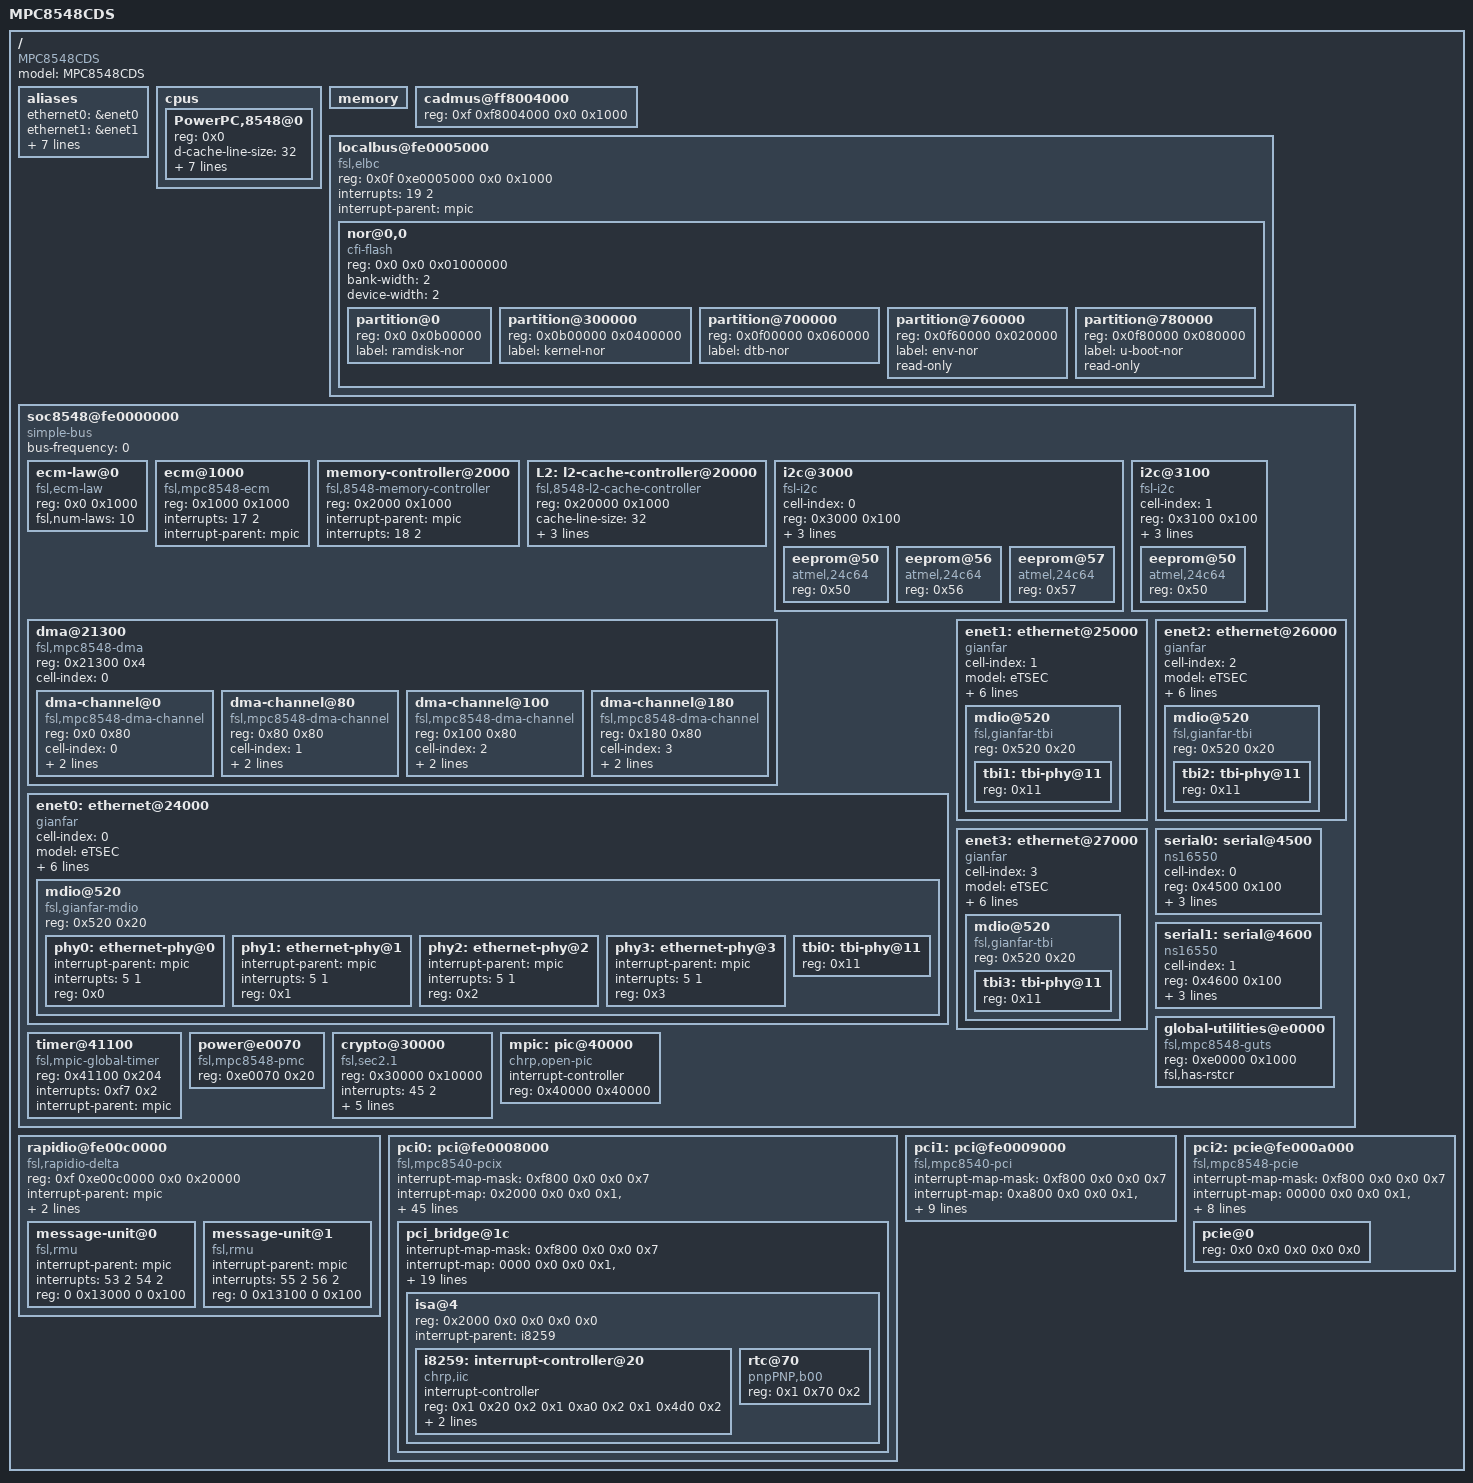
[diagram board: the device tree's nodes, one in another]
/*
 * MPC8548 CDS Device Tree Source
 *
 * Copyright 2011 Freescale Semiconductor Inc.
 *
 * This program is free software; you can redistribute  it and/or modify it
 * under  the terms of  the GNU General  Public License as published by the
 * Free Software Foundation;  either version 2 of the  License, or (at your
 * option) any later version.
 */

/dts-v1/;

/ {
	model = "MPC8548CDS";
	compatible = "MPC8548CDS", "MPC85xxCDS";
	#address-cells = <2>;
	#size-cells = <2>;

	aliases {
		ethernet0 = &enet0;
		ethernet1 = &enet1;
		ethernet2 = &enet2;
		ethernet3 = &enet3;
		serial0 = &serial0;
		serial1 = &serial1;
		pci0 = &pci0;
		pci1 = &pci1;
		pci2 = &pci2;
	};

	cpus {
		#address-cells = <1>;
		#size-cells = <0>;

		PowerPC,8548@0 {
			device_type = "cpu";
			reg = <0x0>;
			d-cache-line-size = <32>;	// 32 bytes
			i-cache-line-size = <32>;	// 32 bytes
			d-cache-size = <0x8000>;		// L1, 32K
			i-cache-size = <0x8000>;		// L1, 32K
			timebase-frequency = <0>;	//  33 MHz, from uboot
			bus-frequency = <0>;	// 166 MHz
			clock-frequency = <0>;	// 825 MHz, from uboot
			next-level-cache = <&L2>;
		};
	};

	memory {
		device_type = "memory";
	};

	cadmus@ff8004000 {
		device_type = "cadmus";
		reg = <0xf 0xf8004000 0x0 0x1000>;
	};

	localbus@fe0005000 {
		#address-cells = <2>;
		#size-cells = <1>;
		compatible = "fsl,elbc", "simple-bus";
		reg = <0x0f 0xe0005000 0x0 0x1000>;
		interrupts = <19 2>;
		interrupt-parent = <&mpic>;

		ranges = <0x0 0x0 0x0f 0xff000000 0x01000000>;

		nor@0,0 {
			#address-cells = <1>;
			#size-cells = <1>;
			compatible = "cfi-flash";
			reg = <0x0 0x0 0x01000000>;
			bank-width = <2>;
			device-width = <2>;

			partition@0 {
				reg = <0x0 0x0b00000>;
				label = "ramdisk-nor";
			};

			partition@300000 {
				reg = <0x0b00000 0x0400000>;
				label = "kernel-nor";
			};

			partition@700000 {
				reg = <0x0f00000 0x060000>;
				label = "dtb-nor";
			};

			partition@760000 {
				reg = <0x0f60000 0x020000>;
				label = "env-nor";
				read-only;
			};

			partition@780000 {
				reg = <0x0f80000 0x080000>;
				label = "u-boot-nor";
				read-only;
			};
		};
	};

	soc8548@fe0000000 {
		#address-cells = <1>;
		#size-cells = <1>;
		device_type = "soc";
		compatible = "simple-bus";
		ranges = <0x0 0xf 0xe0000000 0x100000>;
		bus-frequency = <0>;

		ecm-law@0 {
			compatible = "fsl,ecm-law";
			reg = <0x0 0x1000>;
			fsl,num-laws = <10>;
		};

		ecm@1000 {
			compatible = "fsl,mpc8548-ecm", "fsl,ecm";
			reg = <0x1000 0x1000>;
			interrupts = <17 2>;
			interrupt-parent = <&mpic>;
		};

		memory-controller@2000 {
			compatible = "fsl,8548-memory-controller";
			reg = <0x2000 0x1000>;
			interrupt-parent = <&mpic>;
			interrupts = <18 2>;
		};

		L2: l2-cache-controller@20000 {
			compatible = "fsl,8548-l2-cache-controller";
			reg = <0x20000 0x1000>;
			cache-line-size = <32>;	// 32 bytes
			cache-size = <0x80000>;	// L2, 512K
			interrupt-parent = <&mpic>;
			interrupts = <16 2>;
		};

		i2c@3000 {
			#address-cells = <1>;
			#size-cells = <0>;
			cell-index = <0>;
			compatible = "fsl-i2c";
			reg = <0x3000 0x100>;
			interrupts = <43 2>;
			interrupt-parent = <&mpic>;
			dfsrr;

			eeprom@50 {
				compatible = "atmel,24c64";
				reg = <0x50>;
			};

			eeprom@56 {
				compatible = "atmel,24c64";
				reg = <0x56>;
			};

			eeprom@57 {
				compatible = "atmel,24c64";
				reg = <0x57>;
			};
		};

		i2c@3100 {
			#address-cells = <1>;
			#size-cells = <0>;
			cell-index = <1>;
			compatible = "fsl-i2c";
			reg = <0x3100 0x100>;
			interrupts = <43 2>;
			interrupt-parent = <&mpic>;
			dfsrr;

			eeprom@50 {
				compatible = "atmel,24c64";
				reg = <0x50>;
			};
		};

		dma@21300 {
			#address-cells = <1>;
			#size-cells = <1>;
			compatible = "fsl,mpc8548-dma", "fsl,eloplus-dma";
			reg = <0x21300 0x4>;
			ranges = <0x0 0x21100 0x200>;
			cell-index = <0>;
			dma-channel@0 {
				compatible = "fsl,mpc8548-dma-channel",
						"fsl,eloplus-dma-channel";
				reg = <0x0 0x80>;
				cell-index = <0>;
				interrupt-parent = <&mpic>;
				interrupts = <20 2>;
			};
			dma-channel@80 {
				compatible = "fsl,mpc8548-dma-channel",
						"fsl,eloplus-dma-channel";
				reg = <0x80 0x80>;
				cell-index = <1>;
				interrupt-parent = <&mpic>;
				interrupts = <21 2>;
			};
			dma-channel@100 {
				compatible = "fsl,mpc8548-dma-channel",
						"fsl,eloplus-dma-channel";
				reg = <0x100 0x80>;
				cell-index = <2>;
				interrupt-parent = <&mpic>;
				interrupts = <22 2>;
			};
			dma-channel@180 {
				compatible = "fsl,mpc8548-dma-channel",
						"fsl,eloplus-dma-channel";
				reg = <0x180 0x80>;
				cell-index = <3>;
				interrupt-parent = <&mpic>;
				interrupts = <23 2>;
			};
		};

		enet0: ethernet@24000 {
			#address-cells = <1>;
			#size-cells = <1>;
			cell-index = <0>;
			device_type = "network";
			model = "eTSEC";
			compatible = "gianfar";
			reg = <0x24000 0x1000>;
			ranges = <0x0 0x24000 0x1000>;
			local-mac-address = [ 00 00 00 00 00 00 ];
			interrupts = <29 2 30 2 34 2>;
			interrupt-parent = <&mpic>;
			tbi-handle = <&tbi0>;
			phy-handle = <&phy0>;

			mdio@520 {
				#address-cells = <1>;
				#size-cells = <0>;
				compatible = "fsl,gianfar-mdio";
				reg = <0x520 0x20>;

				phy0: ethernet-phy@0 {
					interrupt-parent = <&mpic>;
					interrupts = <5 1>;
					reg = <0x0>;
					device_type = "ethernet-phy";
				};
				phy1: ethernet-phy@1 {
					interrupt-parent = <&mpic>;
					interrupts = <5 1>;
					reg = <0x1>;
					device_type = "ethernet-phy";
				};
				phy2: ethernet-phy@2 {
					interrupt-parent = <&mpic>;
					interrupts = <5 1>;
					reg = <0x2>;
					device_type = "ethernet-phy";
				};
				phy3: ethernet-phy@3 {
					interrupt-parent = <&mpic>;
					interrupts = <5 1>;
					reg = <0x3>;
					device_type = "ethernet-phy";
				};
				tbi0: tbi-phy@11 {
					reg = <0x11>;
					device_type = "tbi-phy";
				};
			};
		};

		enet1: ethernet@25000 {
			#address-cells = <1>;
			#size-cells = <1>;
			cell-index = <1>;
			device_type = "network";
			model = "eTSEC";
			compatible = "gianfar";
			reg = <0x25000 0x1000>;
			ranges = <0x0 0x25000 0x1000>;
			local-mac-address = [ 00 00 00 00 00 00 ];
			interrupts = <35 2 36 2 40 2>;
			interrupt-parent = <&mpic>;
			tbi-handle = <&tbi1>;
			phy-handle = <&phy1>;

			mdio@520 {
				#address-cells = <1>;
				#size-cells = <0>;
				compatible = "fsl,gianfar-tbi";
				reg = <0x520 0x20>;

				tbi1: tbi-phy@11 {
					reg = <0x11>;
					device_type = "tbi-phy";
				};
			};
		};

		enet2: ethernet@26000 {
			#address-cells = <1>;
			#size-cells = <1>;
			cell-index = <2>;
			device_type = "network";
			model = "eTSEC";
			compatible = "gianfar";
			reg = <0x26000 0x1000>;
			ranges = <0x0 0x26000 0x1000>;
			local-mac-address = [ 00 00 00 00 00 00 ];
			interrupts = <31 2 32 2 33 2>;
			interrupt-parent = <&mpic>;
			tbi-handle = <&tbi2>;
			phy-handle = <&phy2>;

			mdio@520 {
				#address-cells = <1>;
				#size-cells = <0>;
				compatible = "fsl,gianfar-tbi";
				reg = <0x520 0x20>;

				tbi2: tbi-phy@11 {
					reg = <0x11>;
					device_type = "tbi-phy";
				};
			};
		};

		enet3: ethernet@27000 {
			#address-cells = <1>;
			#size-cells = <1>;
			cell-index = <3>;
			device_type = "network";
			model = "eTSEC";
			compatible = "gianfar";
			reg = <0x27000 0x1000>;
			ranges = <0x0 0x27000 0x1000>;
			local-mac-address = [ 00 00 00 00 00 00 ];
			interrupts = <37 2 38 2 39 2>;
			interrupt-parent = <&mpic>;
			tbi-handle = <&tbi3>;
			phy-handle = <&phy3>;

			mdio@520 {
				#address-cells = <1>;
				#size-cells = <0>;
				compatible = "fsl,gianfar-tbi";
				reg = <0x520 0x20>;

				tbi3: tbi-phy@11 {
					reg = <0x11>;
					device_type = "tbi-phy";
				};
			};
		};

		serial0: serial@4500 {
			cell-index = <0>;
			device_type = "serial";
			compatible = "ns16550";
			reg = <0x4500 0x100>;	// reg base, size
			clock-frequency = <0>;	// should we fill in in uboot?
			interrupts = <42 2>;
			interrupt-parent = <&mpic>;
		};

		serial1: serial@4600 {
			cell-index = <1>;
			device_type = "serial";
			compatible = "ns16550";
			reg = <0x4600 0x100>;	// reg base, size
			clock-frequency = <0>;	// should we fill in in uboot?
			interrupts = <42 2>;
			interrupt-parent = <&mpic>;
		};

		global-utilities@e0000 {	//global utilities reg
			compatible = "fsl,mpc8548-guts";
			reg = <0xe0000 0x1000>;
			fsl,has-rstcr;
		};

		timer@41100 {
			compatible = "fsl,mpic-global-timer";
			reg = <0x41100 0x204>;
			interrupts = <0xf7 0x2>;
			interrupt-parent = <&mpic>;
		};

		power@e0070 {
			compatible = "fsl,mpc8548-pmc";
			reg = <0xe0070 0x20>;
		};

		crypto@30000 {
			compatible = "fsl,sec2.1", "fsl,sec2.0";
			reg = <0x30000 0x10000>;
			interrupts = <45 2>;
			interrupt-parent = <&mpic>;
			fsl,num-channels = <4>;
			fsl,channel-fifo-len = <24>;
			fsl,exec-units-mask = <0xfe>;
			fsl,descriptor-types-mask = <0x12b0ebf>;
		};

		mpic: pic@40000 {
			interrupt-controller;
			#address-cells = <0>;
			#interrupt-cells = <2>;
			reg = <0x40000 0x40000>;
			compatible = "chrp,open-pic";
			device_type = "open-pic";
		};
	};

	rapidio@fe00c0000 {
		#address-cells = <2>;
		#size-cells = <2>;
		compatible = "fsl,rapidio-delta";
		reg = <0xf 0xe00c0000 0x0 0x20000>;
		ranges = <0x0 0x0 0xc 0x40000000 0x0 0x20000000>;
		interrupt-parent = <&mpic>;
		interrupts = <48 2	/* port_write_irq */
			      49 2	/* bell_outb_irq  */
			      50 2	/* bell_inb_irq   */>;
		fsl,rio-num-ports = <1>;
		message-unit@0 {
			compatible = "fsl,rmu";
			interrupt-parent = <&mpic>;
			interrupts = <53 2	/* msg1_tx_irq */
				      54 2>;	/* msg1_rx_irq */
			reg = <0 0x13000 0 0x100>;
		};
		message-unit@1 {
			compatible = "fsl,rmu";
			interrupt-parent = <&mpic>;
			interrupts = <55 2	/* msg2_tx_irq */
				      56 2>;	/* msg2_rx_irq */
			reg = <0 0x13100 0 0x100>;
		};

	};

	pci0: pci@fe0008000 {
		interrupt-map-mask = <0xf800 0x0 0x0 0x7>;
		interrupt-map = <
			/* IDSEL 0x4 (PCIX Slot 2) */
			0x2000 0x0 0x0 0x1 &mpic 0x0 0x1
			0x2000 0x0 0x0 0x2 &mpic 0x1 0x1
			0x2000 0x0 0x0 0x3 &mpic 0x2 0x1
			0x2000 0x0 0x0 0x4 &mpic 0x3 0x1

			/* IDSEL 0x5 (PCIX Slot 3) */
			0x2800 0x0 0x0 0x1 &mpic 0x1 0x1
			0x2800 0x0 0x0 0x2 &mpic 0x2 0x1
			0x2800 0x0 0x0 0x3 &mpic 0x3 0x1
			0x2800 0x0 0x0 0x4 &mpic 0x0 0x1

			/* IDSEL 0x6 (PCIX Slot 4) */
			0x3000 0x0 0x0 0x1 &mpic 0x2 0x1
			0x3000 0x0 0x0 0x2 &mpic 0x3 0x1
			0x3000 0x0 0x0 0x3 &mpic 0x0 0x1
			0x3000 0x0 0x0 0x4 &mpic 0x1 0x1

			/* IDSEL 0x8 (PCIX Slot 5) */
			0x4000 0x0 0x0 0x1 &mpic 0x0 0x1
			0x4000 0x0 0x0 0x2 &mpic 0x1 0x1
			0x4000 0x0 0x0 0x3 &mpic 0x2 0x1
			0x4000 0x0 0x0 0x4 &mpic 0x3 0x1

			/* IDSEL 0xC (Tsi310 bridge) */
			0x6000 0x0 0x0 0x1 &mpic 0x0 0x1
			0x6000 0x0 0x0 0x2 &mpic 0x1 0x1
			0x6000 0x0 0x0 0x3 &mpic 0x2 0x1
			0x6000 0x0 0x0 0x4 &mpic 0x3 0x1

			/* IDSEL 0x14 (Slot 2) */
			0xa000 0x0 0x0 0x1 &mpic 0x0 0x1
			0xa000 0x0 0x0 0x2 &mpic 0x1 0x1
			0xa000 0x0 0x0 0x3 &mpic 0x2 0x1
			0xa000 0x0 0x0 0x4 &mpic 0x3 0x1

			/* IDSEL 0x15 (Slot 3) */
			0xa800 0x0 0x0 0x1 &mpic 0x1 0x1
			0xa800 0x0 0x0 0x2 &mpic 0x2 0x1
			0xa800 0x0 0x0 0x3 &mpic 0x3 0x1
			0xa800 0x0 0x0 0x4 &mpic 0x0 0x1

			/* IDSEL 0x16 (Slot 4) */
			0xb000 0x0 0x0 0x1 &mpic 0x2 0x1
			0xb000 0x0 0x0 0x2 &mpic 0x3 0x1
			0xb000 0x0 0x0 0x3 &mpic 0x0 0x1
			0xb000 0x0 0x0 0x4 &mpic 0x1 0x1

			/* IDSEL 0x18 (Slot 5) */
			0xc000 0x0 0x0 0x1 &mpic 0x0 0x1
			0xc000 0x0 0x0 0x2 &mpic 0x1 0x1
			0xc000 0x0 0x0 0x3 &mpic 0x2 0x1
			0xc000 0x0 0x0 0x4 &mpic 0x3 0x1

			/* IDSEL 0x1C (Tsi310 bridge PCI primary) */
			0xe000 0x0 0x0 0x1 &mpic 0x0 0x1
			0xe000 0x0 0x0 0x2 &mpic 0x1 0x1
			0xe000 0x0 0x0 0x3 &mpic 0x2 0x1
			0xe000 0x0 0x0 0x4 &mpic 0x3 0x1>;

		interrupt-parent = <&mpic>;
		interrupts = <24 2>;
		bus-range = <0 0>;
		ranges = <0x2000000 0x0 0xe0000000 0xc 0x00000000 0x0 0x10000000
			  0x1000000 0x0 0x00000000 0xf 0xe2000000 0x0 0x800000>;
		clock-frequency = <66666666>;
		#interrupt-cells = <1>;
		#size-cells = <2>;
		#address-cells = <3>;
		reg = <0xf 0xe0008000 0x0 0x1000>;
		compatible = "fsl,mpc8540-pcix", "fsl,mpc8540-pci";
		device_type = "pci";

		pci_bridge@1c {
			interrupt-map-mask = <0xf800 0x0 0x0 0x7>;
			interrupt-map = <

				/* IDSEL 0x00 (PrPMC Site) */
				0000 0x0 0x0 0x1 &mpic 0x0 0x1
				0000 0x0 0x0 0x2 &mpic 0x1 0x1
				0000 0x0 0x0 0x3 &mpic 0x2 0x1
				0000 0x0 0x0 0x4 &mpic 0x3 0x1

				/* IDSEL 0x04 (VIA chip) */
				0x2000 0x0 0x0 0x1 &mpic 0x0 0x1
				0x2000 0x0 0x0 0x2 &mpic 0x1 0x1
				0x2000 0x0 0x0 0x3 &mpic 0x2 0x1
				0x2000 0x0 0x0 0x4 &mpic 0x3 0x1

				/* IDSEL 0x05 (8139) */
				0x2800 0x0 0x0 0x1 &mpic 0x1 0x1

				/* IDSEL 0x06 (Slot 6) */
				0x3000 0x0 0x0 0x1 &mpic 0x2 0x1
				0x3000 0x0 0x0 0x2 &mpic 0x3 0x1
				0x3000 0x0 0x0 0x3 &mpic 0x0 0x1
				0x3000 0x0 0x0 0x4 &mpic 0x1 0x1

				/* IDESL 0x07 (Slot 7) */
				0x3800 0x0 0x0 0x1 &mpic 0x3 0x1
				0x3800 0x0 0x0 0x2 &mpic 0x0 0x1
				0x3800 0x0 0x0 0x3 &mpic 0x1 0x1
				0x3800 0x0 0x0 0x4 &mpic 0x2 0x1>;

			reg = <0xe000 0x0 0x0 0x0 0x0>;
			#interrupt-cells = <1>;
			#size-cells = <2>;
			#address-cells = <3>;
			ranges = <0x2000000 0x0 0xe0000000
				  0x2000000 0x0 0xe0000000
				  0x0 0x20000000
				  0x1000000 0x0 0x0
				  0x1000000 0x0 0x0
				  0x0 0x80000>;
			clock-frequency = <33333333>;

			isa@4 {
				device_type = "isa";
				#interrupt-cells = <2>;
				#size-cells = <1>;
				#address-cells = <2>;
				reg = <0x2000 0x0 0x0 0x0 0x0>;
				ranges = <0x1 0x0 0x1000000 0x0 0x0 0x1000>;
				interrupt-parent = <&i8259>;

				i8259: interrupt-controller@20 {
					interrupt-controller;
					device_type = "interrupt-controller";
					reg = <0x1 0x20 0x2
					       0x1 0xa0 0x2
					       0x1 0x4d0 0x2>;
					#address-cells = <0>;
					#interrupt-cells = <2>;
					compatible = "chrp,iic";
					interrupts = <0 1>;
					interrupt-parent = <&mpic>;
				};

				rtc@70 {
					compatible = "pnpPNP,b00";
					reg = <0x1 0x70 0x2>;
				};
			};
		};
	};

	pci1: pci@fe0009000 {
		interrupt-map-mask = <0xf800 0x0 0x0 0x7>;
		interrupt-map = <

			/* IDSEL 0x15 */
			0xa800 0x0 0x0 0x1 &mpic 0xb 0x1
			0xa800 0x0 0x0 0x2 &mpic 0x1 0x1
			0xa800 0x0 0x0 0x3 &mpic 0x2 0x1
			0xa800 0x0 0x0 0x4 &mpic 0x3 0x1>;

		interrupt-parent = <&mpic>;
		interrupts = <25 2>;
		bus-range = <0 0>;
		ranges = <0x2000000 0x0 0xe0000000 0xc 0x10000000 0x0 0x10000000
			  0x1000000 0x0 0x00000000 0xf 0xe2800000 0x0 0x800000>;
		clock-frequency = <66666666>;
		#interrupt-cells = <1>;
		#size-cells = <2>;
		#address-cells = <3>;
		reg = <0xf 0xe0009000 0x0 0x1000>;
		compatible = "fsl,mpc8540-pci";
		device_type = "pci";
	};

	pci2: pcie@fe000a000 {
		interrupt-map-mask = <0xf800 0x0 0x0 0x7>;
		interrupt-map = <

			/* IDSEL 0x0 (PEX) */
			00000 0x0 0x0 0x1 &mpic 0x0 0x1
			00000 0x0 0x0 0x2 &mpic 0x1 0x1
			00000 0x0 0x0 0x3 &mpic 0x2 0x1
			00000 0x0 0x0 0x4 &mpic 0x3 0x1>;

		interrupt-parent = <&mpic>;
		interrupts = <26 2>;
		bus-range = <0 255>;
		ranges = <0x2000000 0x0 0xe0000000 0xc 0x20000000 0x0 0x20000000
			  0x1000000 0x0 0x00000000 0xf 0xe3000000 0x0 0x100000>;
		clock-frequency = <33333333>;
		#interrupt-cells = <1>;
		#size-cells = <2>;
		#address-cells = <3>;
		reg = <0xf 0xe000a000 0x0 0x1000>;
		compatible = "fsl,mpc8548-pcie";
		device_type = "pci";
		pcie@0 {
			reg = <0x0 0x0 0x0 0x0 0x0>;
			#size-cells = <2>;
			#address-cells = <3>;
			device_type = "pci";
			ranges = <0x2000000 0x0 0xe0000000
				  0x2000000 0x0 0xe0000000
				  0x0 0x20000000

				  0x1000000 0x0 0x0
				  0x1000000 0x0 0x0
				  0x0 0x100000>;
		};
	};
};
